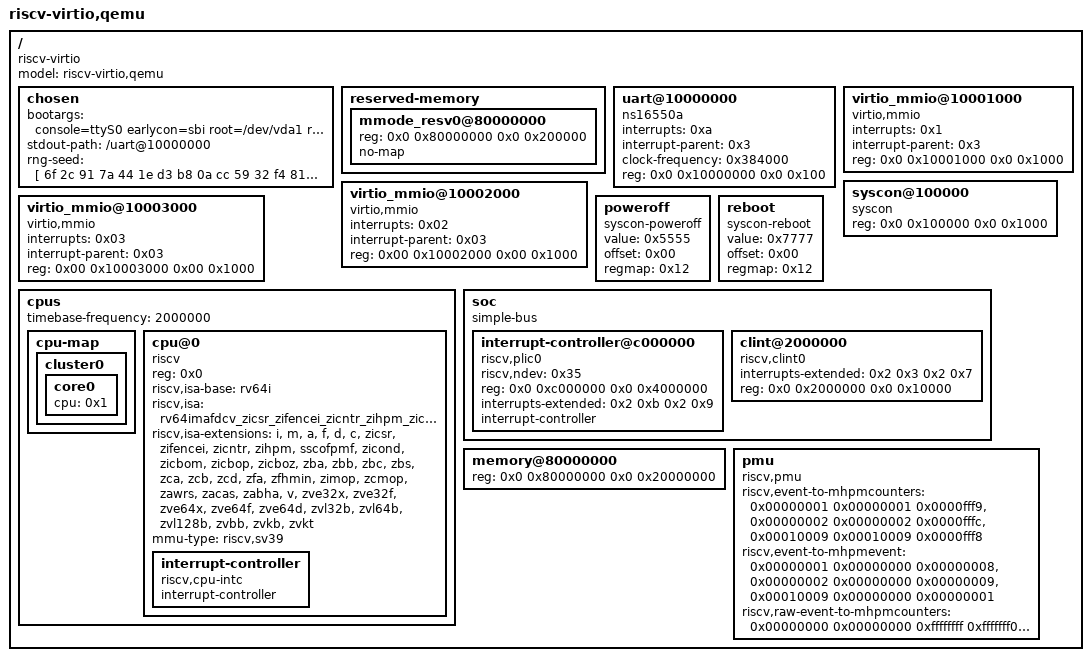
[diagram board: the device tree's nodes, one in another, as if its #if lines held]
/dts-v1/;

/*
 * Compiled into two blobs via the C preprocessor (the cpu node's isa
 * properties are #ifdef VECTOR):
 *   cpp -P -nostdinc -x assembler-with-cpp dts.dts | dtc -I dts -O dtb -o dtb.dtb
 *   cpp -P -DVECTOR -nostdinc -x assembler-with-cpp dts.dts | dtc -I dts -O dtb -o dtb-v.dtb
 * dtb.dtb is the default; dtb-v.dtb is loaded when the -V flag is given.
 */

/ {
        #address-cells = <0x2>;
        #size-cells = <0x2>;
        compatible = "riscv-virtio";
        model = "riscv-virtio,qemu";

        chosen {
		bootargs = "console=ttyS0 earlycon=sbi root=/dev/vda1 rw ignore_loglevel random.trust_bootloader=on";
                stdout-path = "/uart@10000000";

		/* Development-only static seed: replace with per-boot random bytes later. */
		rng-seed = [
			6f 2c 91 7a 44 1e d3 b8
			0a cc 59 32 f4 81 25 9d
			e7 10 ba 6c 38 5f 02 c1
			93 d4 76 af 20 8b ee 41
			15 62 9a cd 57 03 b4 f8
			80 2d 11 6e a9 4c 73 05
			dc 37 f1 98 24 bb 60 0f
			4a e2 7d 36 c5 19 8c a0
		];
        };

        // Reserve the M-mode firmware (OpenSBI) region so S-mode (U-Boot, the
        // kernel) does not treat it as free RAM. QEMU's generated DTB carries
        // the equivalent "mmode_resv0" node; without it, and with PMP not
        // enforced, the kernel allocates over OpenSBI and corrupts its trap
        // handler.
        reserved-memory {
                #address-cells = <0x2>;
                #size-cells = <0x2>;
                ranges;

                mmode_resv0@80000000 {
                        reg = <0x0 0x80000000 0x0 0x200000>;
                        no-map;
                };
        };

        uart@10000000 {
                interrupts = <0xa>;
                interrupt-parent = <0x3>;
                clock-frequency = <0x384000>;
                reg = <0x0 0x10000000 0x0 0x100>;
                compatible = "ns16550a";
        };

        virtio_mmio@10001000 {
                interrupts = <0x1>;
                interrupt-parent = <0x3>;
                reg = <0x0 0x10001000 0x0 0x1000>;
                compatible = "virtio,mmio";
        };

        virtio_mmio@10002000 {
                interrupts = <0x02>;
                interrupt-parent = <0x03>;
                reg = <0x00 0x10002000 0x00 0x1000>;
                compatible = "virtio,mmio";
        };

        virtio_mmio@10003000 {
                interrupts = <0x03>;
                interrupt-parent = <0x03>;
                reg = <0x00 0x10003000 0x00 0x1000>;
                compatible = "virtio,mmio";
        };

        syscon@100000 {
                phandle = <0x12>;
                reg = <0x0 0x100000 0x0 0x1000>;
                compatible = "syscon";
        };

        poweroff {
                value = <0x5555>;
                offset = <0x00>;
                regmap = <0x12>;
                compatible = "syscon-poweroff";
        };

        reboot {
                value = <0x7777>;
                offset = <0x00>;
                regmap = <0x12>;
                compatible = "syscon-reboot";
        };

        cpus {
                #address-cells = <0x1>;
                #size-cells = <0x0>;
                timebase-frequency = <2000000>; // 2 MHz, a 2X lie

                cpu-map {
                        cluster0 {
                                core0 {
                                        cpu = <0x1>;
                                };
                        };
                };

                cpu@0 {
                        phandle = <0x1>;
                        device_type = "cpu";
                        reg = <0x0>;
                        status = "okay";
                        compatible = "riscv";
                        riscv,isa-base = "rv64i";
#ifdef VECTOR
                        /*
                         * The --rva23 machine.  Beyond V this advertises the
                         * RVA23 members we implement, plus the bitmanip and
                         * cache-op extensions the decoder has always had but
                         * the tree never named.
                         * Zvkb is a strict subset of Zvbb, and Zvkt is a
                         * data-independent-latency guarantee with no
                         * instructions, which a functional model meets
                         * trivially.
                         */
                        riscv,isa = "rv64imafdcv_zicsr_zifencei_zicntr_zihpm_zicond_zicbom_zicbop_zicboz_zba_zbb_zbc_zbs_zca_zcb_zcd_zfa_zfhmin_zimop_zcmop_zawrs_zacas_zabha_zvbb_zvkb_zvkt";
                        riscv,isa-extensions = "i", "m", "a", "f", "d", "c", "zicsr", "zifencei", "zicntr", "zihpm", "sscofpmf", "zicond", "zicbom", "zicbop", "zicboz", "zba", "zbb", "zbc", "zbs", "zca", "zcb", "zcd", "zfa", "zfhmin", "zimop", "zcmop", "zawrs", "zacas", "zabha", "v", "zve32x", "zve32f", "zve64x", "zve64f", "zve64d", "zvl32b", "zvl64b", "zvl128b", "zvbb", "zvkb", "zvkt";
#else
                        riscv,isa = "rv64imafdc";
                        riscv,isa-extensions = "i", "m", "a", "f", "d", "c", "zicsr", "zifencei", "zicntr", "zihpm", "sscofpmf";
#endif
                        mmu-type = "riscv,sv39";

                        interrupt-controller {
                                #interrupt-cells = <0x1>;
                                interrupt-controller;
                                compatible = "riscv,cpu-intc";
                                phandle = <0x2>;
                        };
                };
        };

        soc {
                #address-cells = <0x2>;
                #size-cells = <0x2>;
                compatible = "simple-bus";
                ranges;

                interrupt-controller@c000000 {
                        phandle = <0x3>;
                        riscv,ndev = <0x35>;
                        reg = <0x0 0xc000000 0x0 0x4000000>;
                        interrupts-extended = <0x2 0xb 0x2 0x9>;
                        interrupt-controller;
                        compatible = "riscv,plic0";
                        #interrupt-cells = <0x1>;
                        #address-cells = <0x0>;
                };

                clint@2000000 {
                        interrupts-extended = <0x2 0x3 0x2 0x7>;
                        reg = <0x0 0x2000000 0x0 0x10000>;
                        compatible = "riscv,clint0";
                };
        };

        memory@80000000 {
                device_type = "memory";
                reg = <0x0 0x80000000 0x0 0x20000000>;
        };

        /*
         * PMU description consumed by OpenSBI (fdt_pmu_setup).  Without it
         * OpenSBI's hardware-event map is empty and sbi_pmu_event_get_info()
         * answers "unsupported" for every event -- which Linux >= 7.1 uses
         * whenever the firmware speaks SBI 3.0, so even cycles and
         * instructions come back -ENOENT ("<not supported>" in perf stat).
         *
         * CPU_CYCLES/INSTRUCTIONS list the programmable counters as well as
         * their fixed one: mcycle/minstret have no OF or *INH bits (scountovf
         * has no bits below 3), so OpenSBI steers them to an mhpmcounter when
         * Sscofpmf is present -- that is what makes perf record and
         * cycles:u / cycles:k work -- and falls back to the fixed counter only
         * when all 13 are busy.  Selector values are csr::HPM_EV_* in
         * src/csr.rs, and must be non-zero or OpenSBI refuses the counter.
         */
        pmu {
                compatible = "riscv,pmu";

                /* <event_idx_start event_idx_end counter_bitmap> */
                riscv,event-to-mhpmcounters =
                        <0x00000001 0x00000001 0x0000fff9>,   /* cycles       */
                        <0x00000002 0x00000002 0x0000fffc>,   /* instructions */
                        <0x00010009 0x00010009 0x0000fff8>;   /* L1I rd miss  */

                /* <event_idx select_hi select_lo> */
                riscv,event-to-mhpmevent =
                        <0x00000001 0x00000000 0x00000008>,
                        <0x00000002 0x00000000 0x00000009>,
                        <0x00010009 0x00000000 0x00000001>;

                /*
                 * <select_hi select_lo mask_hi mask_lo counter_bitmap>
                 * Raw selectors 0..15 on mhpmcounter3..15:
                 *   r1 uop/bb miss  r2 cold miss  r3 conflict miss
                 *   r4 block hit    r5 flushes    r6 itlb miss  r7 dtlb miss
                 *   r8 cycles       r9 instructions
                 * e.g. "perf stat -e r1,r4 ./prog".
                 */
                riscv,raw-event-to-mhpmcounters =
                        <0x00000000 0x00000000 0xffffffff 0xfffffff0 0x0000fff8>;
        };
};
